# G32R502 register map
Vendor: Geehy Semiconductor Co., Ltd.; Series: G32R5; File version: 1.0
CPU: CM52 r0p1, little endian, MPU, FPU, DSP, VTOR, 4 interrupt priority bits
Registers are 32-bit, read-write, reset 0x0 unless marked. A register's access mark holds for its fields unless they carry their own. Offsets are from the block's base; [hi:lo] are bit positions; {n}, {i} and the like mark numbered series.

## DCS_B0Z1 — Dual Code Security for BANK0 Zone1
Base 0x40010800
0x00 B0_Z1_LINKPOINTER ro reset 0xFFFFFFFF
  [28:0] POINTER — Zone 1 Link Pointer for flash BANK0
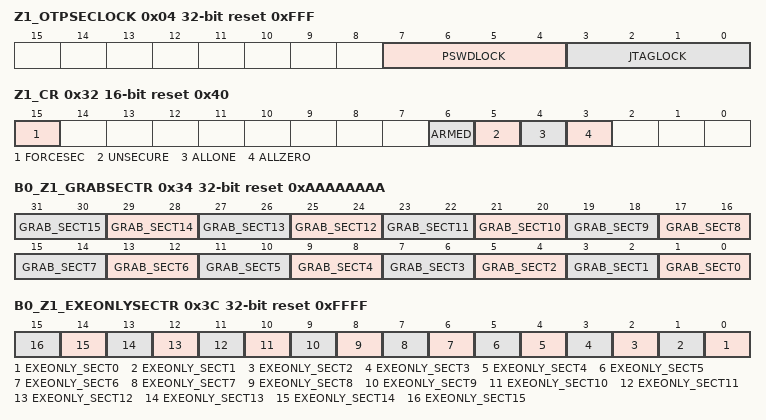
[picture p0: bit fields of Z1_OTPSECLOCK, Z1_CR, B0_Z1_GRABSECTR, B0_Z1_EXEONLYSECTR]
0x04 Z1_OTPSECLOCK ro reset 0xFFF
  [7:4] PSWDLOCK — CS password locations lock
  [3:0] JTAGLOCK
0x08 Z1_BOOTDEF_HIGH ro reset 0xFFFFFFFF
  [31:0] BOOTDEFH — Boot definition high
0x0C B0_Z1_LINKPOINTERERR ro
  [28:0] POINTERERR — Link Pointer error for flash BANK0
0x10 Z1_BOOTPIN_CONFIG ro reset 0xFFFFFFFF
  [31:0] BOOTPINCFG — Boot Pin Configuration
0x14 Z1_GPREG2 ro reset 0xFFFFFFFF
  [31:0] GENPUR — General Purpose Register 2
0x18 Z1_BOOTDEF_LOW ro reset 0xFFFFFFFF
  [31:0] BOOTDEFL — Boot definition Low
0x20 Z1_CSMKEY0
  [31:0] CSKEY0 — Zone 1 CSM Key 0
0x24 Z1_CSMKEY1 ro
  [31:0] CSKEY1 — Zone 1 CSM Key 1
0x28 Z1_CSMKEY2 ro
  [31:0] CSKEY2 — Zone 1 CSM Key 2
0x2C Z1_CSMKEY3
  [31:0] CSKEY3 — Zone 1 CSM Key 3
0x32 Z1_CR 16-bit reset 0x40
  [15] FORCESEC — Zone1 reset
  [6] ARMED ro — Read CS password locations
  [5] UNSECURE ro — Zone1 lock flag
  [4] ALLONE ro — CS Passwords are all one flag
  [3] ALLZERO ro — CS Passwords are all zero flag
0x34 B0_Z1_GRABSECTR ro reset 0xAAAAAAAA
  [2n+1:2n] GRAB_SECT{n} (n=0..15) — Zone 1 Grab Flash BANK0 Sectors x configuration
0x3C B0_Z1_EXEONLYSECTR ro reset 0xFFFF
  [n] EXEONLY_SECT{n} (n=0..15) — Zone 1 Flash BANK0 Sector x Execute_Only disabled

## DCS_B0Z2 — Dual Code Security for BANK0 Zone2
Base 0x40010880
0x00 B0_Z2_LINKPOINTER ro reset 0xFFFFFFFF
  [28:0] POINTER — Zone 2 Link Pointer for flash BANK0
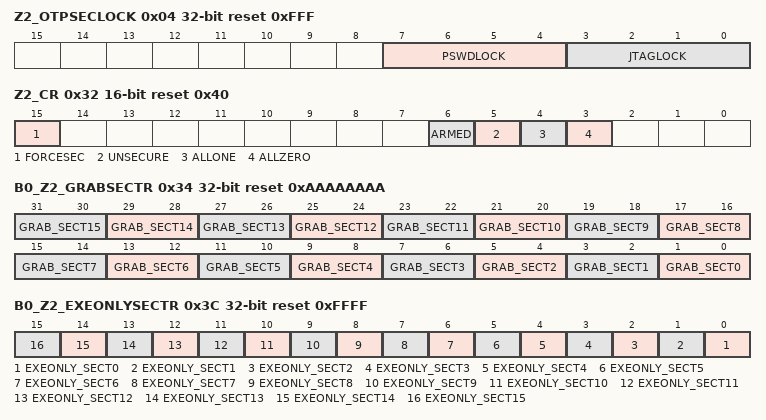
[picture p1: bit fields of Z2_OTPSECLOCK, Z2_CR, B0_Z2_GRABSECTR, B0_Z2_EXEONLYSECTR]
0x04 Z2_OTPSECLOCK ro reset 0xFFF
  [7:4] PSWDLOCK — CS password locations lock
  [3:0] JTAGLOCK
0x0C B0_Z2_LINKPOINTERERR ro
  [28:0] POINTERERR — Link Pointer error for flash BANK0
0x20 Z2_CSMKEY0 ro
  [31:0] CSKEY0 — Zone 2 CSM Key 0
{0x20+4i} Z2_CSMKEY{i} (i=1..3)
  [31:0] CSKEY{i} — Zone 2 CSM Key {i}
0x32 Z2_CR 16-bit reset 0x40
  [15] FORCESEC — Zone2 reset
  [6] ARMED ro — Read CS password locations
  [5] UNSECURE ro — Zone1 lock flag
  [4] ALLONE ro — CS Passwords are all one flag
  [3] ALLZERO ro — CS Passwords are all zero flag
0x34 B0_Z2_GRABSECTR ro reset 0xAAAAAAAA
  [2n+1:2n] GRAB_SECT{n} (n=0..15) — Zone 2 Grab Flash BANK0 Sectors x configuration
0x3C B0_Z2_EXEONLYSECTR ro reset 0xFFFF
  [n] EXEONLY_SECT{n} (n=0..15) — Zone 2 Flash BANK0 Sector x Execute_Only disabled

## DCS_COMMON — Dual Code Security for common
Base 0x400108E0
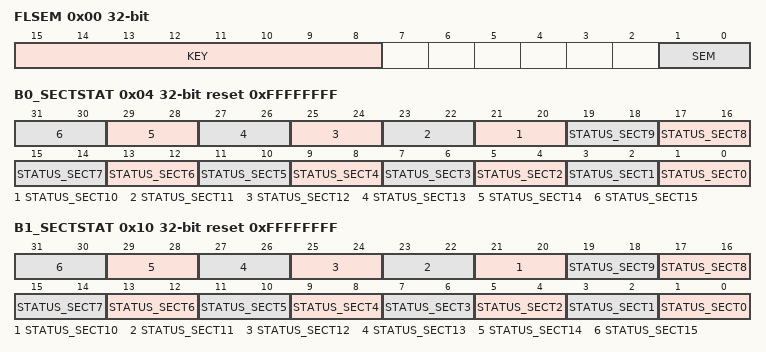
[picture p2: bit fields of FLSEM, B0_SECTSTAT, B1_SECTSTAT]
0x00 FLSEM
  [15:8] KEY
  [1:0] SEM — Flash Wrapper written mode configuration
0x04 B0_SECTSTAT ro reset 0xFFFFFFFF
  [2n+1:2n] STATUS_SECT{n} (n=0..15) — Flash BANK0 Sector x Flag
0x10 B1_SECTSTAT ro reset 0xFFFFFFFF
  [2n+1:2n] STATUS_SECT{n} (n=0..15) — Flash BANK1 Sector x Flag
0x14 SECERRSTAT ro
  [0] ERR — Error loading security configuration from USER OTP Flag
0x18 SECERRCLR
  [0] ERR — Clear Security Configuration Load Error Status Bit
0x1C SECERRFRC
  [0] SECERRFRC — SECERRSTAT ERR Set

## DCS_B1Z1 — Dual Code Security for BANK1 Zone1
Base 0x40010A00
0x00 B1_Z1_LINKPOINTER ro reset 0xFFFFFFFF
  [28:0] POINTER — Zone 1 Link Pointer for flash BANK1
0x0C B1_Z1_LINKPOINTERERR ro
  [28:0] POINTERERR — Link Pointer error for flash BANK1
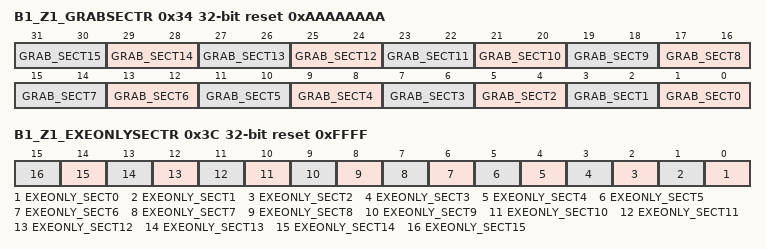
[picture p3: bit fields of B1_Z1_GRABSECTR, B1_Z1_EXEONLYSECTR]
0x34 B1_Z1_GRABSECTR ro reset 0xAAAAAAAA
  [2n+1:2n] GRAB_SECT{n} (n=0..15) — Zone 1 Grab Flash BANK1 Sectors x configuration
0x3C B1_Z1_EXEONLYSECTR ro reset 0xFFFF
  [n] EXEONLY_SECT{n} (n=0..15) — Zone 1 Flash BANK1 Sector x Execute_Only disabled

## DCS_B1Z2 — Dual Code Security for BANK1 Zone2
Base 0x40010A80
0x00 B1_Z2_LINKPOINTER ro reset 0xFFFFFFFF
  [28:0] POINTER — Zone 2 Link Pointer for flash BANK1
0x0C B1_Z2_LINKPOINTERERR ro
  [28:0] POINTERERR — Link Pointer error for flash BANK1
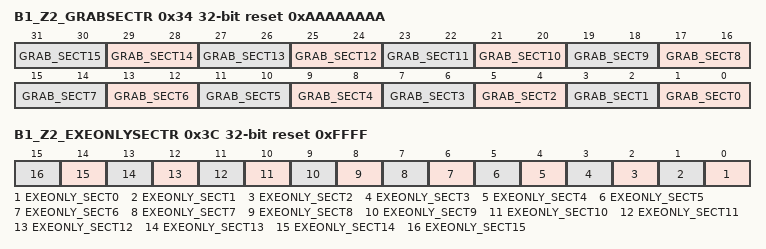
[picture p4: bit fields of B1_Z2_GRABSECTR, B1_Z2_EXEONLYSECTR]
0x34 B1_Z2_GRABSECTR ro reset 0xAAAAAAAA
  [2n+1:2n] GRAB_SECT{n} (n=0..15) — Zone 2 Grab Flash BANK1 Sectors x configuration
0x3C B1_Z2_EXEONLYSECTR ro reset 0xFFFF
  [n] EXEONLY_SECT{n} (n=0..15) — Zone 2 Flash BANK1 Sector x Execute_Only disabled
